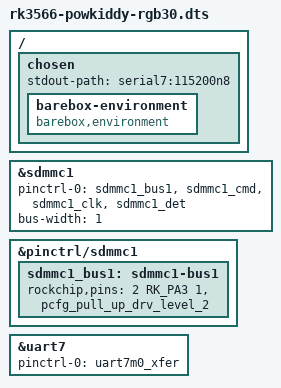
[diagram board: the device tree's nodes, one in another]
// SPDX-License-Identifier: (GPL-2.0+ OR MIT)
/*
 * The RGB30 has no dedicated serial port, so this overlay muxes
 * it out via a SD-Card breakout board in the TF-OS slot:
 *   TXD <- D2
 *   RXD -> D3/CD
 *   GND -- GND
 */

/dts-v1/;

#include <arm64/rockchip/rk3566-powkiddy-rgb30.dts>
#include "rk356x.dtsi"

/ {
	chosen {
		stdout-path = "serial7:115200n8";

		barebox-environment {
			compatible = "barebox,environment";
		};
	};
};

&sdmmc1 {
	pinctrl-0 = <&sdmmc1_bus1 &sdmmc1_cmd &sdmmc1_clk &sdmmc1_det>;
	bus-width = <1>;
};

&{pinctrl/sdmmc1} {
	sdmmc1_bus1: sdmmc1-bus1 {
		rockchip,pins =
			/* sdmmc1_d0 */
			<2 RK_PA3 1 &pcfg_pull_up_drv_level_2>;
	};
};

&uart7 {
	pinctrl-0 = <&uart7m0_xfer>;
	pinctrl-names = "default";
	status = "okay";
};
